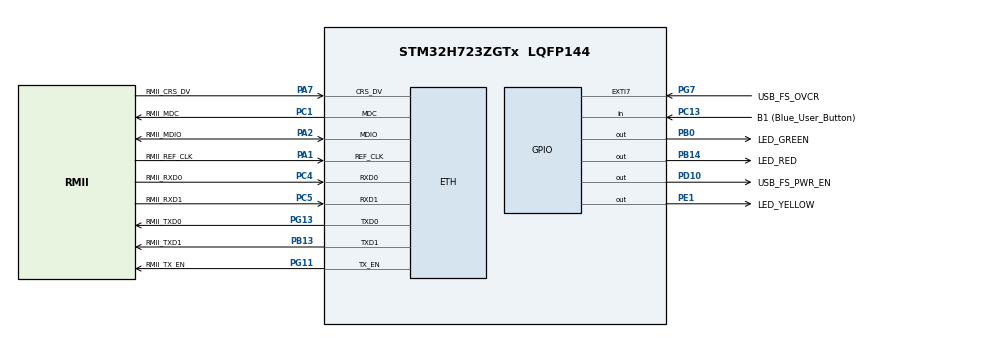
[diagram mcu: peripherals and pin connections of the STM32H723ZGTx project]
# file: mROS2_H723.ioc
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CORTEX_M7.AccessPermission_S-Cortex_Memory_Protection_Unit_Region1_Settings_S=MPU_REGION_FULL_ACCESS
CORTEX_M7.AccessPermission_S-Cortex_Memory_Protection_Unit_Region2_Settings_S=MPU_REGION_FULL_ACCESS
CORTEX_M7.BaseAddress_S-Cortex_Memory_Protection_Unit_Region1_Settings_S=0x30000000
CORTEX_M7.BaseAddress_S-Cortex_Memory_Protection_Unit_Region2_Settings_S=0x30000000
CORTEX_M7.CPU_DCache=Enabled
CORTEX_M7.CPU_ICache=Enabled
CORTEX_M7.DisableExec_S-Cortex_Memory_Protection_Unit_Region1_Settings_S=MPU_INSTRUCTION_ACCESS_DISABLE
CORTEX_M7.DisableExec_S-Cortex_Memory_Protection_Unit_Region2_Settings_S=MPU_INSTRUCTION_ACCESS_DISABLE
CORTEX_M7.Enable_S-Cortex_Memory_Protection_Unit_Region1_Settings_S=MPU_REGION_ENABLE
CORTEX_M7.Enable_S-Cortex_Memory_Protection_Unit_Region2_Settings_S=MPU_REGION_ENABLE
CORTEX_M7.IsBufferable_S-Cortex_Memory_Protection_Unit_Region2_Settings_S=MPU_ACCESS_BUFFERABLE
CORTEX_M7.IsShareable_S-Cortex_Memory_Protection_Unit_Region2_Settings_S=MPU_ACCESS_SHAREABLE
CORTEX_M7.Size_S-Cortex_Memory_Protection_Unit_Region1_Settings_S=MPU_REGION_SIZE_32KB
CORTEX_M7.Size_S-Cortex_Memory_Protection_Unit_Region2_Settings_S=MPU_REGION_SIZE_512B
CORTEX_M7.TypeExtField_S-Cortex_Memory_Protection_Unit_Region1_Settings_S=MPU_TEX_LEVEL1
CORTEX_M7.default_mode_Activation=1
ETH.MediaInterface=HAL_ETH_RMII_MODE
ETH.RxBuffAddress=0x30000200
ETH.RxBuffLen=1536
ETH.TxDescAddress=0x30000100
FREERTOS.Tasks01=defaultTask,24,512,StartDefaultTask,Default,NULL,Dynamic,NULL,NULL
FREERTOS.configCHECK_FOR_STACK_OVERFLOW=1
FREERTOS.configMINIMAL_STACK_SIZE=512
FREERTOS.configTOTAL_HEAP_SIZE=30*1024
FREERTOS.configUSE_NEWLIB_REENTRANT=1
LWIP.BSP.number=1
LWIP.DEFAULT_THREAD_STACKSIZE=2048
LWIP.IP_ADDRESS=192.168.000.103
LWIP.LWIP_DHCP=0
LWIP.LWIP_RAM_HEAP_POINTER=0x30000200
LWIP.MEM_SIZE=32232
LWIP.NETMASK_ADDRESS=255.255.255.000
LWIP.TCPIP_THREAD_STACKSIZE=2048
LWIP.TCP_MSS=1460
LWIP.TCP_SND_BUF=5840
LWIP.TCP_SND_QUEUELEN=16
LWIP.Version=v2.1.2_Cube
LWIP0.BSP.STBoard=false
LWIP0.BSP.api=BSP_COMPONENT_DRIVER
LWIP0.BSP.component=LAN8742
LWIP0.BSP.instance=LAN8742
LWIP0.BSP.name=Driver_PHY
LWIP0.BSP.semaphore=S_LAN8742
LWIP0.BSP.solution=LAN8742
Mcu.Family=STM32H7
Mcu.Name=STM32H723ZGTx
Mcu.Package=LQFP144
NVIC.ETH_IRQn=true\:5\:0\:false\:false\:true\:true\:true\:true\:true
NVIC.PriorityGroup=NVIC_PRIORITYGROUP_4
NVIC.TIM6_DAC_IRQn=true\:15\:0\:false\:false\:true\:false\:false\:true\:true
NVIC.TimeBase=TIM6_DAC_IRQn
NVIC.TimeBaseIP=TIM6
PA1.GPIO_Label=RMII_REF_CLK
PA1.GPIO_Speed=GPIO_SPEED_FREQ_VERY_HIGH
PA1.Mode=RMII
PA1.Signal=ETH_REF_CLK
PA10.GPIO_Label=USB_FS_ID
PA10.Signal=USB_OTG_HS_ID
PA13(JTMS/SWDIO).GPIO_Label=SWDIO
PA13(JTMS/SWDIO).Signal=DEBUG_JTMS-SWDIO
PA14(JTCK/SWCLK).GPIO_Label=SWCLK
PA14(JTCK/SWCLK).Signal=DEBUG_JTCK-SWCLK
PA2.GPIO_Label=RMII_MDIO
PA2.GPIO_Speed=GPIO_SPEED_FREQ_VERY_HIGH
PA2.Mode=RMII
PA2.Signal=ETH_MDIO
PA7.GPIO_Label=RMII_CRS_DV
PA7.GPIO_Speed=GPIO_SPEED_FREQ_VERY_HIGH
PA7.Mode=RMII
PA7.Signal=ETH_CRS_DV
PA9.GPIO_Label=USB_FS_VBUS
PA9.Signal=USB_OTG_HS_VBUS
PB0.GPIO_Label=LED_GREEN
PB0.Signal=GPIO_Output
PB13.GPIO_Label=RMII_TXD1
PB13.GPIO_Speed=GPIO_SPEED_FREQ_VERY_HIGH
PB13.Mode=RMII
PB13.Signal=ETH_TXD1
PB14.GPIO_Label=LED_RED
PB14.Signal=GPIO_Output
PB3(JTDO/TRACESWO).GPIO_Label=SWO
PB3(JTDO/TRACESWO).Signal=DEBUG_JTDO-SWO
PC1.GPIO_Label=RMII_MDC
PC1.GPIO_Speed=GPIO_SPEED_FREQ_VERY_HIGH
PC1.Mode=RMII
PC1.Signal=ETH_MDC
PC13.GPIO_Label=B1 (Blue_User_Button)
PC13.Signal=GPIO_Input
PC14-OSC32_IN.Signal=RCC_OSC32_IN
PC15-OSC32_OUT.Signal=RCC_OSC32_OUT
PC4.GPIO_Label=RMII_RXD0
PC4.GPIO_Speed=GPIO_SPEED_FREQ_VERY_HIGH
PC4.Mode=RMII
PC4.Signal=ETH_RXD0
PC5.GPIO_Label=RMII_RXD1
PC5.GPIO_Speed=GPIO_SPEED_FREQ_VERY_HIGH
PC5.Mode=RMII
PC5.Signal=ETH_RXD1
PD10.GPIO_Label=USB_FS_PWR_EN
PD10.Signal=GPIO_Output
PD8.GPIO_Label=STLK_VCP_RX
PD8.Signal=USART3_TX
PD9.GPIO_Label=STLK_VCP_TX
PD9.Signal=USART3_RX
PE1.GPIO_Label=LED_YELLOW
PE1.Signal=GPIO_Output
PG11.GPIO_Label=RMII_TX_EN
PG11.GPIO_Speed=GPIO_SPEED_FREQ_VERY_HIGH
PG11.Mode=RMII
PG11.Signal=ETH_TX_EN
PG13.GPIO_Label=RMII_TXD0
PG13.GPIO_Speed=GPIO_SPEED_FREQ_VERY_HIGH
PG13.Mode=RMII
PG13.Signal=ETH_TXD0
PG7.GPIO_Label=USB_FS_OVCR
PG7.Signal=GPXTI7
PH0-OSC_IN.GPIO_Label=MCO
PH0-OSC_IN.Signal=RCC_OSC_IN
PH1-OSC_OUT.Signal=RCC_OSC_OUT
ProjectManager.HeapSize=0x200
ProjectManager.StackSize=0x400
ProjectManager.TargetToolchain=STM32CubeIDE
RCC.ADCFreq_Value=608000000
RCC.APB1Freq_Value=125000000
RCC.APB2Freq_Value=125000000
RCC.APB3Freq_Value=125000000
RCC.APB4Freq_Value=125000000
RCC.CortexFreq_Value=500000000
RCC.D1PPRE=RCC_APB3_DIV2
RCC.D2PPRE1=RCC_APB1_DIV2
RCC.D2PPRE2=RCC_APB2_DIV2
RCC.D3PPRE=RCC_APB4_DIV2
RCC.DIVM1=16
RCC.DIVM2=1
RCC.DIVN1=125
RCC.DIVN2=19
RCC.DIVP1=1
RCC.DIVQ1=4
RCC.HCLKFreq_Value=250000000
RCC.HPRE=RCC_HCLK_DIV2
RCC.HSE_VALUE=8000000
RCC.PLLFRACN=0
RCC.SYSCLKFreq_VALUE=500000000
RCC.SYSCLKSource=RCC_SYSCLKSOURCE_PLLCLK
RCC.USBCLockSelection=RCC_USBCLKSOURCE_HSI48
RCC.USBFreq_Value=48000000
VP_FREERTOS_VS_CMSIS_V2.Mode=CMSIS_V2
VP_LWIP_VS_Enabled.Mode=Enabled
VP_SYS_VS_tim6.Mode=TIM6
board=NUCLEO-H723ZG

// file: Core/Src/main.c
/* USER CODE BEGIN Header */
/**
  ******************************************************************************
  * @file           : main.c
  * @brief          : Main program body
  ******************************************************************************
  * @attention
  *
  * Copyright (c) 2022 STMicroelectronics.
  * All rights reserved.
  *
  * This software is licensed under terms that can be found in the LICENSE file
  * in the root directory of this software component.
  * If no LICENSE file comes with this software, it is provided AS-IS.
  *
  ******************************************************************************
  */
/* USER CODE END Header */
#include "main.h"
#include "cmsis_os.h"
#include "lwip.h"
#include "gpio.h"

/* USER CODE BEGIN Includes */
/* ETH_CODE: add lwiperf, see comment in StartDefaultTask function */
#include "lwip/apps/lwiperf.h"
/* USER CODE END Includes */

void SystemClock_Config(void);
static void MPU_Config(void);
void MX_FREERTOS_Init(void);

int main(void)
{

  /* MPU Configuration--------------------------------------------------------*/
  MPU_Config();

  /* Enable I-Cache---------------------------------------------------------*/
  SCB_EnableICache();

  /* Enable D-Cache---------------------------------------------------------*/
  SCB_EnableDCache();

  /* MCU Configuration--------------------------------------------------------*/

  /* Reset of all peripherals, Initializes the Flash interface and the Systick. */
  HAL_Init();

  /* Configure the system clock */
  SystemClock_Config();

  /* Initialize all configured peripherals */
  MX_GPIO_Init();

  /* Init scheduler */
  osKernelInitialize();  /* Call init function for freertos objects (in freertos.c) */
  MX_FREERTOS_Init();

  /* Start scheduler */
  osKernelStart();

  /* We should never get here as control is now taken by the scheduler */
  /* Infinite loop */
  while (1)
  {

  }
}

void SystemClock_Config(void)
{
  RCC_OscInitTypeDef RCC_OscInitStruct = {0};
  RCC_ClkInitTypeDef RCC_ClkInitStruct = {0};

  /** Supply configuration update enable
  */
  HAL_PWREx_ConfigSupply(PWR_LDO_SUPPLY);

  /** Configure the main internal regulator output voltage
  */
  __HAL_PWR_VOLTAGESCALING_CONFIG(PWR_REGULATOR_VOLTAGE_SCALE0);

  while(!__HAL_PWR_GET_FLAG(PWR_FLAG_VOSRDY)) {}

  /** Initializes the RCC Oscillators according to the specified parameters
  * in the RCC_OscInitTypeDef structure.
  */
  RCC_OscInitStruct.OscillatorType = RCC_OSCILLATORTYPE_HSI;
  RCC_OscInitStruct.HSIState = RCC_HSI_DIV1;
  RCC_OscInitStruct.HSICalibrationValue = RCC_HSICALIBRATION_DEFAULT;
  RCC_OscInitStruct.PLL.PLLState = RCC_PLL_ON;
  RCC_OscInitStruct.PLL.PLLSource = RCC_PLLSOURCE_HSI;
  RCC_OscInitStruct.PLL.PLLM = 16;
  RCC_OscInitStruct.PLL.PLLN = 125;
  RCC_OscInitStruct.PLL.PLLP = 1;
  RCC_OscInitStruct.PLL.PLLQ = 4;
  RCC_OscInitStruct.PLL.PLLR = 2;
  RCC_OscInitStruct.PLL.PLLRGE = RCC_PLL1VCIRANGE_2;
  RCC_OscInitStruct.PLL.PLLVCOSEL = RCC_PLL1VCOWIDE;
  RCC_OscInitStruct.PLL.PLLFRACN = 0;
  if (HAL_RCC_OscConfig(&RCC_OscInitStruct) != HAL_OK)
  {
    Error_Handler();
  }

  /** Initializes the CPU, AHB and APB buses clocks
  */
  RCC_ClkInitStruct.ClockType = RCC_CLOCKTYPE_HCLK|RCC_CLOCKTYPE_SYSCLK
                              |RCC_CLOCKTYPE_PCLK1|RCC_CLOCKTYPE_PCLK2
                              |RCC_CLOCKTYPE_D3PCLK1|RCC_CLOCKTYPE_D1PCLK1;
  RCC_ClkInitStruct.SYSCLKSource = RCC_SYSCLKSOURCE_PLLCLK;
  RCC_ClkInitStruct.SYSCLKDivider = RCC_SYSCLK_DIV1;
  RCC_ClkInitStruct.AHBCLKDivider = RCC_HCLK_DIV2;
  RCC_ClkInitStruct.APB3CLKDivider = RCC_APB3_DIV2;
  RCC_ClkInitStruct.APB1CLKDivider = RCC_APB1_DIV2;
  RCC_ClkInitStruct.APB2CLKDivider = RCC_APB2_DIV2;
  RCC_ClkInitStruct.APB4CLKDivider = RCC_APB4_DIV2;

  if (HAL_RCC_ClockConfig(&RCC_ClkInitStruct, FLASH_LATENCY_3) != HAL_OK)
  {
    Error_Handler();
  }
}

/* MPU Configuration */

void MPU_Config(void)
{
  MPU_Region_InitTypeDef MPU_InitStruct = {0};

  /* Disables the MPU */
  HAL_MPU_Disable();

  /** Initializes and configures the Region and the memory to be protected
  */
  MPU_InitStruct.Enable = MPU_REGION_ENABLE;
  MPU_InitStruct.Number = MPU_REGION_NUMBER0;
  MPU_InitStruct.BaseAddress = 0x0;
  MPU_InitStruct.Size = MPU_REGION_SIZE_4GB;
  MPU_InitStruct.SubRegionDisable = 0x87;
  MPU_InitStruct.TypeExtField = MPU_TEX_LEVEL0;
  MPU_InitStruct.AccessPermission = MPU_REGION_NO_ACCESS;
  MPU_InitStruct.DisableExec = MPU_INSTRUCTION_ACCESS_DISABLE;
  MPU_InitStruct.IsShareable = MPU_ACCESS_SHAREABLE;
  MPU_InitStruct.IsCacheable = MPU_ACCESS_NOT_CACHEABLE;
  MPU_InitStruct.IsBufferable = MPU_ACCESS_NOT_BUFFERABLE;

  HAL_MPU_ConfigRegion(&MPU_InitStruct);

  /** Initializes and configures the Region and the memory to be protected
  */
  MPU_InitStruct.Number = MPU_REGION_NUMBER1;
  MPU_InitStruct.BaseAddress = 0x30000000;
  MPU_InitStruct.Size = MPU_REGION_SIZE_32KB;
  MPU_InitStruct.SubRegionDisable = 0x0;
  MPU_InitStruct.TypeExtField = MPU_TEX_LEVEL1;
  MPU_InitStruct.AccessPermission = MPU_REGION_FULL_ACCESS;
  MPU_InitStruct.IsShareable = MPU_ACCESS_NOT_SHAREABLE;

  HAL_MPU_ConfigRegion(&MPU_InitStruct);

  /** Initializes and configures the Region and the memory to be protected
  */
  MPU_InitStruct.Number = MPU_REGION_NUMBER2;
  MPU_InitStruct.Size = MPU_REGION_SIZE_512B;
  MPU_InitStruct.TypeExtField = MPU_TEX_LEVEL0;
  MPU_InitStruct.IsShareable = MPU_ACCESS_SHAREABLE;
  MPU_InitStruct.IsBufferable = MPU_ACCESS_BUFFERABLE;

  HAL_MPU_ConfigRegion(&MPU_InitStruct);
  /* Enables the MPU */
  HAL_MPU_Enable(MPU_PRIVILEGED_DEFAULT);

}

void HAL_TIM_PeriodElapsedCallback(TIM_HandleTypeDef *htim)
{
  if (htim->Instance == TIM6) {
    HAL_IncTick();
  }
}

void Error_Handler(void)
{
  __disable_irq();
  while (1)
  {
  }
}
